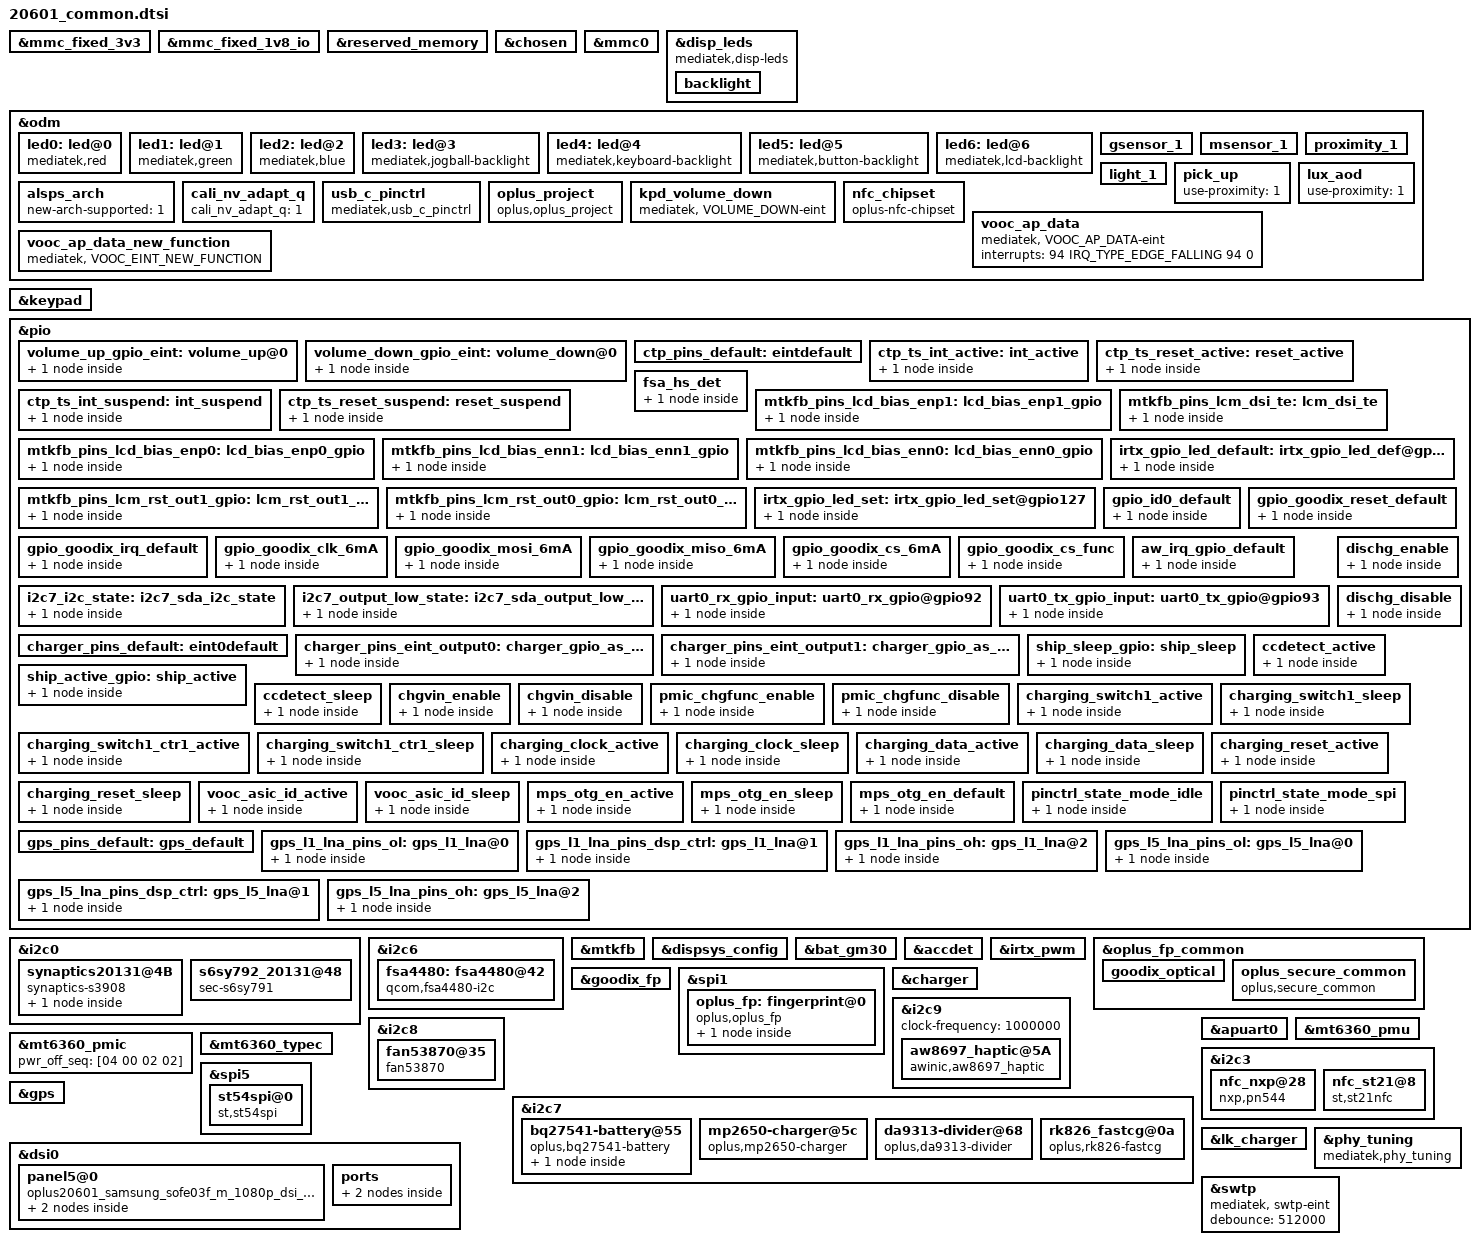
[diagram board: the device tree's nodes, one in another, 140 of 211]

&mmc_fixed_3v3 {
	status = "okay";
	regulator-name = "mmc_power";
	regulator-min-microvolt = <3300000>;
	regulator-max-microvolt = <3300000>;
	enable-active-high;
	regulator-always-on;
};

&mmc_fixed_1v8_io {
	status = "okay";
	regulator-name = "mmc_io";
	regulator-min-microvolt = <1800000>;
	regulator-max-microvolt = <1800000>;
	enable-active-high;
	regulator-always-on;
};

&reserved_memory {
};

/* chosen */
&chosen {

	atag,videolfb-fb_base_l = <0x7e020000>;
	atag,videolfb-fb_base_h = <0x0>;
	atag,videolfb-islcmfound = <1>;
	atag,videolfb-islcm_inited = <0>;
	atag,videolfb-fps= <6000>;
	atag,videolfb-vramSize= <0x1be0000>;
	atag,videolfb-lcmname=
		"nt35595_fhd_dsi_cmd_truly_nt50358_drv";
};

&mmc0 {
	status = "okay";
	/* pinctrl-names = "default", "state_uhs"; */
	/* pinctrl-0 = <&mmc0_pins_default>; */
	/* pinctrl-1 = <&mmc0_pins_uhs>; */
	bus-width = <8>;
	max-frequency = <5000000>;
	cap-mmc-highspeed;
	no-sdio;
	no-sd;
	vmmc-supply = <&mmc_fixed_3v3>;
	vqmmc-supply = <&mmc_fixed_1v8_io>;
	non-removable;
};

&disp_leds {
        compatible = "mediatek,disp-leds";
        backlight {
                label = "lcd-backlight";
                max-brightness = <4095>;
                led-bits = <12>;
                trans-bits = <12>;
                default-state = "on";
        };
};

&odm {
	led0:led@0 {
		compatible = "mediatek,red";
		led_mode = <0>;
		data = <1>;
		pwm_config = <0 0 0 0 0>;
	};
	led1:led@1 {
		compatible = "mediatek,green";
		led_mode = <0>;
		data = <1>;
		pwm_config = <0 0 0 0 0>;
	};
	led2:led@2 {
		compatible = "mediatek,blue";
		led_mode = <0>;
		data = <1>;
		pwm_config = <0 0 0 0 0>;
	};
	led3:led@3 {
		compatible = "mediatek,jogball-backlight";
		led_mode = <0>;
		data = <1>;
		pwm_config = <0 0 0 0 0>;
	};
	led4:led@4 {
		compatible = "mediatek,keyboard-backlight";
		led_mode = <0>;
		data = <1>;
		pwm_config = <0 0 0 0 0>;
	};
	led5:led@5 {
		compatible = "mediatek,button-backlight";
		led_mode = <0>;
		data = <1>;
		pwm_config = <0 0 0 0 0>;
	};
	led6:led@6 {
		compatible = "mediatek,lcd-backlight";
		//led_mode = <5>;
		//#else
		led_mode = <4>;
		//#endif
		data = <1>;
		pwm_config = <0 1 0 0 0>;
	};

/* sensor start */
	/*
	enum {
		LIS3DH,
		LSM6DS3,
		BMI160,
		LIS2HH12,
		LSM6DSM,
		BMI2XY,
		LSM6DSO,
	};
	*/
	gsensor_1: gsensor_1 {
		status = "okay";
		sensor_name = <2>;//BMI160
		device_name = "bmi160";
		i2c_num = <2>;
		i2c_addr = <0>;
		direction = <7>;
		eint_num = <3>;
		step_count_7_en = <1>;
		config_miso = <0>;
		correct_y_bias = <0>;
		cali_nv_adapt_q_flag = <1>;
	};

	/*
	enum {
		AKM09911,
		MMC3530,
		MMC5603,
		MXG4300,
	};
	*/
	msensor_1: msensor_1 {
		status = "okay";
		sensor_name = <0>;//AKM09911
		i2c_num = <0>;
		i2c_addr = <12>;
		direction = <2>;
		eint_num = <0>;
		soft-mag-parameter = <9237 0 1513 0 780 0 1513 0 10462 0 778 1 780 0 778 1 10745 0>;
	};
	/*
	enum {
		TMD2725,
		APSD9922,
		STK3335,
		STK3331,
		STK2232,
		TCS3701,
		STK32600,
		STK33502,
	};
	*/
		proximity_1: proximity_1 {
		status = "okay";
		sensor_name = <7>;//STK33502
		i2c_num = <0>;
		i2c_addr = <0x46>;
		direction = <4>;
		eint_num = <4>;
		low_step = <150>;
		high_step = <200>;
		low_limit = <200>;
		high_limit = <300>;
		dirty_low_step = <100>;
		dirty_high_step = <150>;
		ps_dirty_limit = <1023>;
		ps_ir_limit = <500>;
		ps_adjust_min = <0>;
		ps_adjust_max = <600>;
		sampling_count = <5>;
		step_max = <400>;
		step_min = <100>;
		step_div = <2000>;
		anti_shake_delta = <70>;
		dynamic_cali_max = <3000>;
		raw2offset_radio = <1000>;
		offset_max = <60000>;
		offset_range_min = <0>;
		offset_range_max = <65534>;
		force_cali_limit = <2000>;
		cali_jitter_limit = <30>;
		cal_offset_margin = <3000>;
	};
	light_1: light_1 {
		status = "okay";
		sensor_name = <7>;//STK33502
		i2c_num = <0>;
		i2c_addr = <0x46>;
		direction = <4>;
		eint_num = <4>;
		als_ratio = <110>;
		als_buffer_length =<4>;
		als_type = <1>;//<1-normal;2-under screen;3-normal needed compensation>
		device_name = "stk33502";
		coefficient_mode = <1>;
	};
	pick_up: pick_up {
		status = "okay";
		use-proximity = <1>;
	};
	lux_aod: lux_aod {
		status = "okay";
		use-proximity = <1>;
	};
	alsps_arch: alsps_arch {
		status = "okay";
		new-arch-supported = <1>;
	};
	cali_nv_adapt_q: cali_nv_adapt_q {
		status = "okay";
		cali_nv_adapt_q = <1>;
	};
/* sensor end */
	usb_c_pinctrl:usb_c_pinctrl {
		compatible = "mediatek,usb_c_pinctrl";
	};
/*OPLUS_FEATURE_TP_BASIC oplus project start */
	oplus_project:oplus_project {
		compatible = "oplus,oplus_project";
	};
/*endif*/
//#ifdef OPLUS_FEATURE_TP_BASIC
        kpd_volume_down:kpd_volume_down {
                compatible = "mediatek, VOLUME_DOWN-eint";
                interrupt-parent = <&pio>;
                interrupts = <155 IRQ_TYPE_EDGE_FALLING 155 0>;
                debounce = <32000>;
                status = "okay";
        };

//#endif OPLUS_FEATURE_TP_BASIC

    nfc_chipset:nfc_chipset {
        compatible = "oplus-nfc-chipset";
        chipset-20131 = "SN100T";
        chipset-20601 = "ST54H";
        chipset-20602 = "ST54H";
        chipset-20660 = "ST21H";
    };
//#endif /* OPLUS_FEATURE_NFC_CONSOFT */
};
//#ifdef OPLUS_FEATURE_TP_BASIC
&keypad {
        keypad,volume-up        = <&pio 20 0x00>;
        keypad,volume-down      = <&pio 155 0x00>;
        pinctrl-names = "volume_up_as_int", "volume_down_as_int";
        pinctrl-0 = <&volume_up_gpio_eint>;
        pinctrl-1 = <&volume_down_gpio_eint>;
        status = "okay";
};

&pio {
        volume_up_gpio_eint:volume_up@0{
                pins_cmd_dat {
                        pinmux = <PINMUX_GPIO59__FUNC_GPIO59>;
                        slew-rate = <0>;  /*direction 0:in, 1:out*/
                        input-enable;
                };
        };

        volume_down_gpio_eint:volume_down@0{
                pins_cmd_dat {
                        pinmux = <PINMUX_GPIO155__FUNC_GPIO155>;
                        slew-rate = <0>;  /*direction 0:in, 1:out*/
                        input-enable;
                };
        };
};
//#endif OPLUS_FEATURE_TP_BASIC
//#ifdef OPLUS_FEATURE_TP_BASIC
&i2c0 {

	synaptics20131@4B {
		compatible = "synaptics-s3908";
		reg = <0x4B>;
		chip-name = "S3908";

		/* Interrupt && Irq-gpio */
		interrupt-parent = <&pio>;
		interrupts = <21 0x2008>;

		/* Power Config */
		vdd_2v8-supply  = <&mt_pmic_vtp_ldo_reg>;
		vdd_2v8_volt = <3000000>;
		/* Other HW Resource */

		irq-gpio = <&pio 21 0x2008>;
		reset-gpio = <&pio 20 0x1>;
		pinctrl-names = "default";
		pinctrl-0 = <&ctp_ts_int_active &ctp_ts_reset_suspend>;

		touchpanel,max-num-support = <10>;
		touchpanel,tx-rx-num = <16 36>;
		touchpanel,panel-coords = <1080 2400>;
		touchpanel,display-coords = <1080 2400>;
		touchpanel,touchmajor-limit = <32 54>;
		//touchpanel,elimination-range = <20 200 200>;
		touchpanel,int-mode = <1>; /*0: interrupt and disable, 1:interrupt and not disable*/
		touchpanel,smooth-level = <0 1 2 3 8 10>;
		touchpanel,sensitive-level = <0 88 70 64 45 10>;
		vid_len = <2>;
		tp_type = <8>; /*type:8 BOE*/
		platform_support_project = <20131 20133 20255 20257 20601 20602 20660>;
		platform_support_project_dir = <20131 20131 20131 20131 20601 20601 20601>;
                platform_support_project_commandline = "oplus20131_boe_nt37800_1080p_dsi_cmd","oplus20131_boe_nt37800_1080p_dsi_cmd","oplus20131_boe_nt37800_1080p_dsi_cmd","oplus20131_boe_nt37800_1080p_dsi_cmd","default_commandline","default_commandline","default_commandline";
		/* SW Support Feature Control */
		black_gesture_support;
		fw_edge_limit_support;
		charger_pump_support;
		//spurious_fingerprint_support;
		fw_update_app_support;
		smart_gesture_support;
		game_switch_support;
		//kernel_grip_support;
		//health_monitor_support;
		fingerprint_underscreen_support;
		freq_hop_simulate_support;
		report_flow_unlock_support;
		screenoff_fingerprint_info_support;
		headset_pump_support;
		pressure_report_support;
		irq_need_dev_resume_ok;

		/*
		 *Virtual Key Config:
		 *1:touchpanel,button-type: <virtualkey_type  supportted_button-map>
		 *virtualkey_type:
		 *Type 1: using board_properties
		 *Type 2: using same IC (button zone&& touch zone are seprate)
		 *Type 3: using diffrent IC (button zone&& touch zone are seprate)
		 *Type 4: No need of virtual key process
		 *supportted_button-map:select|menu|home|back
		 *
		 *2:touchpanel,button-map
		 *type (X1,Y1)(X2,Y2)(X3,Y3)(Width_X,Hight_Y)--Only when button-type is 0
		 */
		touchpanel,button-type = <4>;
		touchpanel.button-TRx = <0 0>;
		S3908 {
			report_rate_default = <60>;
			report_rate_game_value = <2>;
		};
	};

	s6sy792_20131@48 {
		compatible = "sec-s6sy791";
		reg = <0x48>;
		chip-name = "S6SY792";

                /* Interrupt && Irq-gpio */
                interrupt-parent = <&pio>;
                interrupts = <21 0x2008>;

                /* Power Config */
                vdd_2v8-supply  = <&mt_pmic_vtp_ldo_reg>;
                vdd_2v8_volt = <3000000>;
                /* Other HW Resource */

                irq-gpio = <&pio 21 0x2008>;
                reset-gpio = <&pio 20 0x1>;
                pinctrl-names = "default";
                pinctrl-0 = <&ctp_ts_int_active &ctp_ts_reset_suspend>;


		touchpanel,max-num-support = <10>;
                touchpanel,tx-rx-num = <16 36>;
                touchpanel,panel-coords = <1080 2400>;
                touchpanel,display-coords = <1080 2400>;
                touchpanel,touchmajor-limit = <32 54>;
                //touchpanel,elimination-range = <20 200 200>;

                vid_len = <2>;
                tp_type = <8>; /*type:8 SAMSUNG*/
                platform_support_project = <20131 20133 20255 20257>;
        	platform_support_project_dir = <20131 20131 20131 20131>;
                platform_support_project_commandline = "oplus20131_samsung_ana6705_1080p_dsi_cmd","oplus20131_samsung_ana6705_1080p_dsi_cmd","oplus20131_samsung_ana6705_1080p_dsi_cmd","oplus20131_samsung_ana6705_1080p_dsi_cmd";

                /* SW Support Feature Control */
                black_gesture_support;
                //fw_edge_limit_support;
                charger_pump_support;
                //spurious_fingerprint_support;
                fw_update_app_support;
                smart_gesture_support;
                game_switch_support;
                //kernel_grip_support;
                //health_monitor_support;
                fingerprint_underscreen_support;
                headset_pump_support;
                pressure_report_support;

		/*
                 *Virtual Key Config:
                 *1:touchpanel,button-type: <virtualkey_type  supportted_button-map>
                 *virtualkey_type:
                 *Type 1: using board_properties
                 *Type 2: using same IC (button zone&& touch zone are seprate)
                 *Type 3: using diffrent IC (button zone&& touch zone are seprate)
                 *Type 4: No need of virtual key process
                 *supportted_button-map:select|menu|home|back
                 *
                 *2:touchpanel,button-map
                 *type (X1,Y1)(X2,Y2)(X3,Y3)(Width_X,Hight_Y)--Only when button-type is 0
                 */
                touchpanel,button-type = <4>;
                touchpanel.button-TRx = <0 0>;
	};
};

&pio {
	ctp_pins_default: eintdefault {
	};
	ctp_ts_int_active: int_active {
		pins_cmd_dat {
			pinmux = <PINMUX_GPIO21__FUNC_GPIO21>;
			slew-rate = <0>;
			bias-pull-up;
		};
	};
	ctp_ts_reset_active: reset_active {
		pins_cmd_dat {
			pinmux = <PINMUX_GPIO20__FUNC_GPIO20>;
			slew-rate = <1>;
			output-high;
		};
	};
	ctp_ts_int_suspend: int_suspend {
		pins_cmd_dat {
			pinmux = <PINMUX_GPIO21__FUNC_GPIO21>;
			slew-rate = <1>;
			output-low;
		};
	};
	ctp_ts_reset_suspend: reset_suspend {
		pins_cmd_dat {
			pinmux = <PINMUX_GPIO20__FUNC_GPIO20>;
			slew-rate = <1>;
			output-low;
		};
	};
};
//#endif OPLUS_FEATURE_TP_BASIC

//#ifdef OPLUS_ARCH_EXTENDS
&i2c6 {
	fsa4480: fsa4480@42 {
		compatible = "qcom,fsa4480-i2c";
		reg = <0x42>;
		pinctrl-names = "default";
		pinctrl-0 = <&fsa_hs_det>;
		fsa4480,hs-det-gpio = <&pio 54 0>;
	};
};

&pio {
	fsa_hs_det: fsa_hs_det {
		pins_cmd_dat {
			pinmux = <PINMUX_GPIO54__FUNC_GPIO54>;
			slew-rate = <1>;  /*direction 0:in, 1:out*/
			output-high;
		};
	};
	/*
	aud_gpio_i2s0_on: aud_gpio_i2s0_on {
		pins_cmd1_dat {
			pinmux = <PINMUX_GPIO34__FUNC_I2S3_DI>;
		};
	};*/
};
//#endif /*OPLUS_ARCH_EXTENDS*/

/* DISPSYS GPIO standardization */
&pio {
	mtkfb_pins_lcd_bias_enp1: lcd_bias_enp1_gpio {
		pins_cmd_dat {
			pinmux = <PINMUX_GPIO28__FUNC_GPIO28>;
			slew-rate = <1>;
			output-high;
		};
	};

	mtkfb_pins_lcd_bias_enp0: lcd_bias_enp0_gpio {
		pins_cmd_dat {
			pinmux = <PINMUX_GPIO28__FUNC_GPIO28>;
			slew-rate = <1>;
			output-low;
		};
	};

	mtkfb_pins_lcd_bias_enn1: lcd_bias_enn1_gpio {
		pins_cmd_dat {
			pinmux = <PINMUX_GPIO29__FUNC_GPIO29>;
			slew-rate = <1>;
			output-high;
		};
	};

	mtkfb_pins_lcd_bias_enn0: lcd_bias_enn0_gpio {
		pins_cmd_dat {
			pinmux = <PINMUX_GPIO29__FUNC_GPIO29>;
			slew-rate = <1>;
			output-low;
		};
	};

	mtkfb_pins_lcm_rst_out1_gpio: lcm_rst_out1_gpio {
		pins_cmd_dat {
			pinmux = <PINMUX_GPIO42__FUNC_GPIO42>;
			slew-rate = <1>;
			output-high;
		};
	};

	mtkfb_pins_lcm_rst_out0_gpio: lcm_rst_out0_gpio {
		pins_cmd_dat {
			pinmux = <PINMUX_GPIO42__FUNC_GPIO42>;
			slew-rate = <1>;
			output-low;
		};
	};

	mtkfb_pins_lcm_dsi_te: lcm_dsi_te {
		pins_cmd_dat {
			pinmux = <PINMUX_GPIO41__FUNC_DSI_TE>;
		};
	};
};

&mtkfb {
	pinctrl-names = "lcd_bias_enp1_gpio", "lcd_bias_enp0_gpio",
		"lcd_bias_enn1_gpio", "lcd_bias_enn0_gpio",
		"lcm_rst_out1_gpio", "lcm_rst_out0_gpio",
		"mode_te_te";
	pinctrl-0 = <&mtkfb_pins_lcd_bias_enp1>;
	pinctrl-1 = <&mtkfb_pins_lcd_bias_enp0>;
	pinctrl-2 = <&mtkfb_pins_lcd_bias_enn1>;
	pinctrl-3 = <&mtkfb_pins_lcd_bias_enn0>;
	pinctrl-4 = <&mtkfb_pins_lcm_rst_out1_gpio>;
	pinctrl-5 = <&mtkfb_pins_lcm_rst_out0_gpio>;
	pinctrl-6 = <&mtkfb_pins_lcm_dsi_te>;
	status = "okay";
};

&dispsys_config {
	pinctrl-names =
		"lcm_rst_out1_gpio", "lcm_rst_out0_gpio",
		"mode_te_te";
	pinctrl-0 = <&mtkfb_pins_lcm_rst_out1_gpio>;
	pinctrl-1 = <&mtkfb_pins_lcm_rst_out0_gpio>;
	pinctrl-2 = <&mtkfb_pins_lcm_dsi_te>;
	status = "okay";

        helper-value = <0>, /*MTK_DRM_OPT_STAGE*/
                <1>, /*MTK_DRM_OPT_USE_CMDQ*/
                <1>, /*MTK_DRM_OPT_USE_M4U*/
                <0>, /*MTK_DRM_OPT_SODI_SUPPORT*/
                <1>, /*MTK_DRM_OPT_IDLE_MGR*/
                <0>, /*MTK_DRM_OPT_IDLEMGR_SWTCH_DECOUPLE*/
                <1>, /*MTK_DRM_OPT_IDLEMGR_BY_REPAINT*/
                <0>, /*MTK_DRM_OPT_IDLEMGR_ENTER_ULPS*/
                <0>, /*MTK_DRM_OPT_IDLEMGR_KEEP_LP11*/
                <0>, /*MTK_DRM_OPT_DYNAMIC_RDMA_GOLDEN_SETTING*/
                <1>, /*MTK_DRM_OPT_IDLEMGR_DISABLE_ROUTINE_IRQ*/
                <0>, /*MTK_DRM_OPT_MET_LOG*/
                <1>, /*MTK_DRM_OPT_USE_PQ*/
                <1>, /*MTK_DRM_OPT_ESD_CHECK_RECOVERY*/
                <1>, /*MTK_DRM_OPT_ESD_CHECK_SWITCH*/
                <1>, /*MTK_DRM_OPT_PRESENT_FENCE*/
                <0>, /*MTK_DRM_OPT_RDMA_UNDERFLOW_AEE*/
                <0>, /*MTK_DRM_OPT_DSI_UNDERRUN_AEE*/
                <1>, /*MTK_DRM_OPT_HRT*/
                <1>, /*MTK_DRM_OPT_HRT_MODE*/
                <0>, /*MTK_DRM_OPT_DELAYED_TRIGGER*/
                <1>, /*MTK_DRM_OPT_OVL_EXT_LAYER*/
                <0>, /*MTK_DRM_OPT_AOD*/
                <1>, /*MTK_DRM_OPT_RPO*/
                <0>, /*MTK_DRM_OPT_DUAL_PIPE*/
                <0>, /*MTK_DRM_OPT_DC_BY_HRT*/
                <1>, /*MTK_DRM_OPT_OVL_WCG*/
                <0>, /*MTK_DRM_OPT_OVL_SBCH*/
                <1>, /*MTK_DRM_OPT_COMMIT_NO_WAIT_VBLANK*/
                <0>, /*MTK_DRM_OPT_MET*/
                <0>, /*MTK_DRM_OPT_REG_PARSER_RAW_DUMP*/
                <0>, /*MTK_DRM_OPT_VP_PQ*/
                <0>, /*MTK_DRM_OPT_GAME_PQ*/
                <0>, /*MTK_DRM_OPT_MMPATH*/
                <1>, /*MTK_DRM_OPT_HBM*/
                <0>, /*MTK_DRM_OPT_VDS_PATH_SWITCH*/
                <0>, /*MTK_DRM_OPT_LAYER_REC*/
                <1>, /*MTK_DRM_OPT_CLEAR_LAYER*/
                <1>, /*MTK_DRM_OPT_SF_PF*/
                <1>, /*MTK_DRM_OPT_PRIM_DUAL_PIPE*/
                <1>; /*MTK_DRM_OPT_DYN_MIPI_CHANGE*/
};

&bat_gm30 {
	DISABLE_MTKBATTERY = <(1)>;
	enable_tmp_intr_suspend = <(1)>;
};

/* DISPSYS GPIO standardization end */

/* accdet start */
&accdet {
	/* accdet micbias voltage: 0x09:2.85v 0x08:2.8v 0x07,
	 * 2.7v;0x05,2.5v;0x02,1.9v
	 */
	accdet-mic-vol = <8>;
	/* accdet pwm_width, pwm_thresh, fall_delay, rise_delay
	 * debounce0, debounce1, debounce3, debounce4
	 * eint pwm_width, eint pwm_thresh
	 * eint deb(debounce0, debounce1, debounce2, debounce3), inv_debounce
	 */
	headset-mode-setting = <0x500 0x500 1 0x1f0
				0x800 0x800 0x20 0x44
				0x4 0x1
				0x5 0x3 0x3 0x5 0xe>;
	accdet-plugout-debounce = <1>;
	/*1:ACC mode, 2:low cost without in bias, 6:low cost with in bias*/
	accdet-mic-mode = <2>;
	/*0--MD_MAX--UP_MAX--DW_MAX*/
	headset-three-key-threshold = <0 82 170 306>;
	headset-three-key-threshold-CDD = <0 121 192 600>;
	/*0--MD_MAX--VOICE_MAX--UP_MAX--DW_MAX*/
	headset-four-key-threshold = <0 58 121 192 400>;

	/* select VTH to 2v and 500k, use internal resitance */
	eint_use_ext_res = <0>;
	status = "okay";

	/* add that is to rm the unplug headset pop */
	remove_unplug_pop = <1>;
};
/* accdet end */

/* IRTX GPIO Start */
&irtx_pwm {
	pinctrl-names = "irtx_gpio_led_default", "irtx_gpio_led_set";
	pinctrl-0 = <&irtx_gpio_led_default>;
	pinctrl-1 = <&irtx_gpio_led_set>;
	status = "okay";
};
&pio {
	/* IRTX GPIO Settings -Start */
	/* default: GPIO0, output, high */
	irtx_gpio_led_default:irtx_gpio_led_def@gpio127 {
		pins_cmd_dat {
			pinmux = <PINMUX_GPIO127__FUNC_GPIO127>;
			slew-rate = <1>;
			bias-disable;
			output-low;
			input-schmitt-enable = <0>;
		};
	};

	irtx_gpio_led_set:irtx_gpio_led_set@gpio127 {
		pins_cmd_dat {
			pinmux = <PINMUX_GPIO127__FUNC_PWM_3>;
			slew-rate = <1>;
			output-high;
		};
	};
}; /* IRTX GPIO Settings -End */

/* FINGERPRINT start */
//ifdef OPLUS_FEATURE_FINGERPRINT
&oplus_fp_common {
    oplus,fp_gpio_num = <1>;
    oplus,fp_gpio_0 = <&pio 190 0x0>;
    pinctrl-names = "default";
    pinctrl-0 = <&gpio_id0_default>;
    goodix_optical {
        oplus,fp-id = <0>; // fp id mapping table
        vendor-chip = <11>; // please refer to the struct fp_vendor_t in oplus_fp_commmon.n
        eng-menu = "-1,-1"; // represents SNR, inclination test item in engineer menu, and 0/1 means off/on
        chip-name = "G_OPTICAL_G6_7.0";  // /proc/fp_id, will be displayed in engineer menu
	};


//#ifdef OPLUS_FEATURE_SECURITY_COMMON
	oplus_secure_common:oplus_secure_common {
		compatible = "oplus,secure_common";
		oplus,sec_reg_num = <0>;
		oplus,sec_en_anti_reg = <0>;
		oplus,sec_override1_reg = <0>;
		oplus,override1_en_value = <0>;
	};
//#endif  OPLUS_FEATURE_SECURITY_COMMON

};

&pio{
	gpio_id0_default: gpio_id0_default {
		pins_cmd_dat {
			pinmux = <PINMUX_GPIO190__FUNC_GPIO190>;
			slew-rate = <0>;
			bias-pull-up = <00>;
			input-enable;
		};
	};
};

&goodix_fp {
	goodix,gpio_irq = <&pio 15 0x00>;
	goodix,gpio_reset = <&pio 14 0x00>;
	goodix,gpio_cs = <&pio 157 0x00>;
	pinctrl-names = "default", "gf_spi_drive_6mA", "gf_cs_func";
	pinctrl-0 = <&gpio_goodix_irq_default>, <&gpio_goodix_reset_default>;
	pinctrl-1 = <&gpio_goodix_clk_6mA>, <&gpio_goodix_mosi_6mA>, <&gpio_goodix_miso_6mA>, <&gpio_goodix_cs_6mA>;
	pinctrl-2 = <&gpio_goodix_cs_func>;
	status = "okay";
};

&spi1 {
#address-cells = <1>;
#size-cells = <0>;
status = "okay";
oplus_fp: fingerprint@0 {
		 compatible = "oplus,oplus_fp";
		 reg = <0>;
		 spi-max-frequency = <8000000>;
		 spi-id = <1>;
		 spi-irq = <39>;
		 spi-reg = <11010000>;
		 avdd-supply = <&mt_pmic_vmch_ldo_reg>;
		 avdd-config = <3300000 3300000 150000>;
		 power-num = <1>;
		 status = "okay";
		 notify_tpinfo_flag = <1>;
		 power_source_1 {
			 power-mode = <1>;
			 power-name = "avdd";
			 power-config = "avdd-config";
			 delay-time = <0>;
		 };
	 };
};
// 1 = ldo power, refer to oplus_fp_common.h
&pio{
gpio_goodix_reset_default: gpio_goodix_reset_default {
				   pins_cmd_dat {
					   pinmux = <PINMUX_GPIO14__FUNC_GPIO14>;
					   slew-rate = <1>;
					   output-low;
				   };
			   };
gpio_goodix_irq_default: gpio_goodix_irq_default {
				 pins_cmd_dat {
					 pinmux = <PINMUX_GPIO15__FUNC_GPIO15>;
					 slew-rate = <0>;
					 bias-pull-down;
				 };
			 };
gpio_goodix_clk_6mA: gpio_goodix_clk_6mA {
			     pins_cmd_dat {
				      pinmux = <PINMUX_GPIO156__FUNC_SPI1_A_CLK>;
				      drive-strength = <2>;
			     };
		     };
gpio_goodix_mosi_6mA: gpio_goodix_mosi_6mA {
			      pins_cmd_dat {
				      pinmux = <PINMUX_GPIO159__FUNC_SPI1_A_MO>;
				      drive-strength = <2>;
			      };
		      };
gpio_goodix_miso_6mA: gpio_goodix_miso_6mA {
			      pins_cmd_dat {
				      pinmux = <PINMUX_GPIO158__FUNC_SPI1_A_MI>;
				      drive-strength = <3>;
			      };
		      };
gpio_goodix_cs_6mA: gpio_goodix_cs_6mA {
			    pins_cmd_dat {
				    pinmux = <PINMUX_GPIO157__FUNC_SPI1_A_CSB>;
				    drive-strength = <2>;
			    };
		    };
gpio_goodix_cs_func: gpio_goodix_cs_func {
			     pins_cmd_dat {
				     pinmux = <PINMUX_GPIO157__FUNC_SPI1_A_CSB>;
				     drive-strength = <2>;
			     };
		     };
};
//#endif
/* FINGERPRINT end */
//#ifdef OPLUS_FEATURE_CHG_BASIC
&charger {
	io-channels = <&auxadc 3>,
		<&auxadc 4>,
		<&auxadc 5>;
	io-channel-names = "auxadc3-chargeric_temp",
		"auxadc4-usb_temp_v_l",
		"auxadc5-usb_temp_v_r";

	pinctrl-names = "default", "charger_gpio_as_output_low", "charger_gpio_as_output_high", "ship_sleep", "ship_active",
		"dischg_enable", "dischg_disable", "chgvin_enable", "chgvin_disable","pmic_chgfunc_enable", "pmic_chgfunc_disable",
		"ccdetect_active","ccdetect_sleep";
	pinctrl-0 = <&charger_pins_default>;
	pinctrl-1 = <&charger_pins_eint_output0>;	//USB_ON -> USB_SWITCH:(UART && USB)
	pinctrl-2 = <&charger_pins_eint_output1>;
	pinctrl-3 = <&ship_sleep_gpio>;				//ship_mode
	pinctrl-4 = <&ship_active_gpio>;
	pinctrl-5 = <&dischg_enable>;				//usb_hightemp_port
	pinctrl-6 = <&dischg_disable>;
	pinctrl-7 = <&chgvin_enable>;					//EVB GPIO30 chgvin
	pinctrl-8 = <&chgvin_disable>;
	pinctrl-9 = <&pmic_chgfunc_enable>;				//EVB GPIO26 chg_enable
	pinctrl-10 = <&pmic_chgfunc_disable>;
	//pinctrl-5 = <&shortc_active_gpio>;
	pinctrl-11 = <&ccdetect_active>;
	pinctrl-12 = <&ccdetect_sleep>;
	qcom,hv_flashled_support;
	qcom,chargerid_support;
	qcom,input_current_charger_ma = <2000>;
	qcom,pd_input_current_charger_ma = <2000>;
	qcom,qc_input_current_charger_ma = <2000>;
	qcom,input_current_usb_ma = <500>;

	qcom,input_current_led_ma = <1200>;
	qcom,input_current_led_ma_high = <1200>;
	qcom,input_current_led_ma_warm = <1500>;
	qcom,input_current_led_ma_normal = <2000>;
	qcom,led_warm_bat_decidegc = <350>;
	qcom,led_high_bat_decidegc = <370>;

	qcom,input_current_camera_ma = <1200>;
	qcom,input_current_cdp_ma = <1500>;

	qcom,input_current_vooc_led_ma_high = <1200>;
	qcom,input_current_vooc_led_ma_warm = <1800>;
	qcom,input_current_vooc_led_ma_normal = <3600>;
	qcom,input_current_vooc_ma_normal = <3600>;
	qcom,vooc_temp_bat_normal_decidegc = <350>;
	qcom,input_current_vooc_ma_warm = <3200>;
	qcom,vooc_temp_bat_warm_decidegc = <370>;
	qcom,input_current_vooc_ma_high = <2200>;
	qcom,vooc_temp_bat_hot_decidegc = <440>;

	qcom,charger_current_vooc_ma_normal = <1800>;

	qcom,chg_ctrl_by_calling;
	qcom,input_current_calling_ma = <1500>;

	qcom,overtemp_bat_decidegc = <350>;
	qcom,iterm_disabled = <0>;
	sw_full_count = <25>;
	qcom,iterm_ma = <115>;
	qcom,recharge-mv = <100>;
	qcom,batt_capacity_mah = <4500>;/*typical capacity*/

	qcom,removed_bat_decidegc = <190>;  /*<-19C*/

	qcom,cold_bat_decidegc = <20>;  /*-2C~0C*/
	qcom,temp_cold_vfloat_mv = <3980>;
	qcom,temp_cold_fastchg_current_ma = <300>;

	qcom,little_cold_bat_decidegc = <0>;    /*0C~5C*/
	qcom,temp_little_cold_vfloat_mv = <4435>;
	qcom,temp_little_cold_fastchg_current_ma_high = <950>;
	qcom,temp_little_cold_fastchg_current_ma_low = <950>;
	qcom,temp_little_cold_fastchg_current_ma = <950>;
	qcom,pd_temp_little_cold_fastchg_current_ma_high = <1800>;
	qcom,pd_temp_little_cold_fastchg_current_ma_low = <1500>;
	qcom,qc_temp_little_cold_fastchg_current_ma_high = <1800>;
	qcom,qc_temp_little_cold_fastchg_current_ma_low = <1500>;

	qcom,cool_bat_decidegc = <50>;  /*5C~12C*/
	qcom,temp_cool_vfloat_mv = <4435>;
	qcom,temp_cool_fastchg_current_ma_high = <1100>;
	qcom,temp_cool_fastchg_current_ma_low = <1100>;
	qcom,pd_temp_cool_fastchg_current_ma_high = <2000>;
	qcom,pd_temp_cool_fastchg_current_ma_low = <1500>;
	qcom,qc_temp_cool_fastchg_current_ma_high = <2000>;
	qcom,qc_temp_cool_fastchg_current_ma_low = <1500>;

	qcom,little_cool_bat_decidegc = <120>;  /*12C~16C*/
	qcom,temp_little_cool_vfloat_mv = <4435>;
	qcom,temp_little_cool_fastchg_current_ma = <1100>;
	qcom,pd_temp_little_cool_fastchg_current_ma = <2000>;
	qcom,qc_temp_little_cool_fastchg_current_ma = <2000>;

	qcom,normal_bat_decidegc = <160>;       /*16C~44C*/
	qcom,temp_normal_fastchg_current_ma = <1100>;
	qcom,temp_normal_vfloat_mv = <4435>;
	qcom,pd_temp_normal_fastchg_current_ma = <2000>;
	qcom,qc_temp_normal_fastchg_current_ma = <2000>;

	qcom,warm_bat_decidegc = <450>;         /*45C~53C*/ /*8pin Bat Vooc project need add 3 degree C*/
	qcom,temp_warm_vfloat_mv = <4130>;
	qcom,temp_warm_fastchg_current_ma = <550>;
	qcom,pd_temp_warm_fastchg_current_ma = <600>;
	qcom,qc_temp_warm_fastchg_current_ma = <600>;
	qcom,temp_warm_fastchg_current_ma_led_on = <250>;

	qcom,hot_bat_decidegc = <530>;

	qcom,non_standard_vfloat_mv = <3980>;
	qcom,non_standard_fastchg_current_ma = <512>;

	qcom,short_c_bat_cv_mv = <4330>;
	qcom,short_c_bat_vfloat_mv = <3800>;
	qcom,short_c_bat_fastchg_current_ma = <512>;

	qcom,cold_vfloat_sw_limit = <3930>;
	qcom,little_cold_vfloat_sw_limit = <4385>;
	qcom,cool_vfloat_sw_limit = <4385>;
	qcom,little_cool_vfloat_sw_limit = <4385>;
	qcom,normal_vfloat_sw_limit = <4385>;
	qcom,warm_vfloat_sw_limit = <4080>;
	qcom,non_standard_vfloat_sw_limit = <3930>;
	qcom,short_c_bat_vfloat_sw_limit = <3750>;

	qcom,max_chg_time_sec = <64800>;
	qcom,charger_hv_thr = <9900>;
	qcom,charger_recv_thr = <9500>;
	qcom,charger_lv_thr = <3400>;
	qcom,vbatt_full_thr = <4435>;
	qcom,vbatt_hv_thr = <4600>;
	qcom,vfloat_step_mv = <8>;
	qcom,non_standard_vfloat_over_sw_limit = <3990>;
	qcom,cold_vfloat_over_sw_limit = <3990>;
	qcom,little_cold_vfloat_over_sw_limit = <4445>;
	qcom,cool_vfloat_over_sw_limit = <4445>;
	qcom,little_cool_vfloat_over_sw_limit = <4445>;
	qcom,normal_vfloat_over_sw_limit = <4445>;
	qcom,warm_vfloat_over_sw_limit = <4140>;

	qcom,vbatt_power_off = <3300>;
	qcom,vbatt_soc_1 = <3310>;
	qcom,vooc_project = <3>;
	qcom,vbatt_num = <2>;
	qcom,new_ui_warning_support;
	qcom,ffc_support;
	qcom,dual_ffc;
	recharge_after_full;

	qcom,normal_vterm_hw_inc = <18>;
	qcom,non_normal_vterm_hw_inc = <18>;

	qcom,ff1_normal_fastchg_ma = <550>;
	qcom,ff1_warm_fastchg_ma = <550>;

	qcom,ffc2_normal_fastchg_ma = <350>;/*12C~35c*/
	qcom,ffc2_temp_warm_decidegc = <350>;
	qcom,ffc2_warm_fastchg_ma = <350>;/*35C~40c*/
	qcom,ffc2_temp_high_decidegc = <400>;
	qcom,ffc2_temp_low_decidegc = <120>;

	qcom,ff1_exit_step_ma = <150>;
	qcom,ff1_warm_exit_step_ma = <150>;
	qcom,ffc2_exit_step_ma = <150>;
	qcom,ffc2_warm_exit_step_ma = <150>;

	qcom,ffc_normal_vfloat_sw_limit = <4455>;
	qcom,ffc_temp_normal_vfloat_mv = <4500>;
	qcom,ffc_normal_vfloat_over_sw_limit = <4500>;
	qcom,ffc_warm_vfloat_sw_limit = <4450>;
	qcom,ffc_temp_warm_vfloat_mv = <4500>;
	qcom,ffc_warm_vfloat_over_sw_limit = <4500>;
	qcom,ffc1_temp_normal_vfloat_mv = <4500>;

	qcom,ffc2_normal_vfloat_sw_limit = <4442>;
	qcom,ffc2_temp_normal_vfloat_mv = <4500>;

	qcom,ffc1_normal_vfloat_over_sw_limit = <4500>;
	qcom,ffc2_normal_vfloat_over_sw_limit = <4500>;
	qcom,ffc2_warm_vfloat_sw_limit = <4437>;
	qcom,ffc2_temp_warm_vfloat_mv = <4500>;
	qcom,ffc2_warm_vfloat_over_sw_limit = <4500>;

	qcom,default_iterm_ma = <115>;
	qcom,default_temp_normal_fastchg_current_ma = <1100>;
	qcom,default_normal_vfloat_sw_limit = <4385>;
	qcom,default_temp_normal_vfloat_mv = <4435>;
	qcom,default_normal_vfloat_over_sw_limit = <4445>;

	qcom,default_temp_little_cool_fastchg_current_ma = <1100>;
	qcom,default_little_cool_vfloat_sw_limit = <4385>;
	qcom,default_temp_little_cool_vfloat_mv = <4435>;
	qcom,default_little_cool_vfloat_over_sw_limit = <4445>;

	qcom,vooc_show_ui_soc_decimal;
	qcom,ui_soc_decimal_speedmin = <20>;//2A
	qcom,check_batt_full_by_sw;
	qcom,external_gauge;
	qcom,chg_ctrl_by_lcd;
	qcom,chg_ctrl_by_vooc;
	qcom,chg_ctrl_by_camera;
	qcom,support_ntc_01c_precision;
	qcom,sw_vfloat_over_protect_enable;
	qcom,lpd-disable;
	//for PD9V or QC9V
	qcom,vbatt_pdqc_to_5v_thr = <4100>;
	qcom,vbatt_pdqc_to_9v_thr = <4000>;

	//GPIO config:
	qcom,chargerid_switch-gpio = <&pio 192 0x00>;//USB_ON
	qcom,ship-gpio = <&pio 126 0x00>;		//check
	qcom,dischg-gpio = <&pio 51 0x00>;//VBUS_SHORT
	//qcom,shortc-gpio = <&pio 121 0x00>;
	qcom,ccdetect-gpio = <&pio 5 0x00>;//USB_ACC_INT

	//Lukaili Add for camera flash led
	qcom,chgvin = <&pio 9 0x00>;		//check
	qcom,pmic_chgfunc = <&pio 26 0x00>;		//check
};
//#endif OPLUS_FEATURE_CHG_BASIC
&i2c9 {
    status = "okay";
	clock-frequency = <1000000>;
	
	/* AWINIC AW8697 Haptic */
	aw8697_haptic@5A {
		status = "okay";
		compatible = "awinic,aw8697_haptic";
		reg = <0x5A>;
		reset-gpio = <&pio 185 0x1>;
		irq-gpio = <&pio 135 0x2008>;
		qcom,device_id = <832>;//19065

		pinctrl-names = "default";
		pinctrl-0 = <&aw_irq_gpio_default>;
	};
};

&i2c8 {
	   fan53870@35 {
               compatible = "fan53870";
               reg = <0x35>;
               ldo1_min_vol = <800000>;  /*uV*/
               ldo1_max_vol = <1504000>;
               ldo1_step_vol = <8000>;
       };
};

&pio{
	aw_irq_gpio_default: aw_irq_gpio_default {		//check
		pins_cmd_dat {
			pinmux = <PINMUX_GPIO135__FUNC_GPIO135>;
			slew-rate = <0>;
			bias-pull-up = <11>;
			input-enable;
		};
	};

};
//#ifdef OPLUS_FEATURE_CHG_BASIC
&odm {
	vooc_ap_data:vooc_ap_data {
		compatible = "mediatek, VOOC_AP_DATA-eint";
		interrupts = <94 IRQ_TYPE_EDGE_FALLING 94 0>;
	};
	vooc_ap_data_new_function:vooc_ap_data_new_function {
		compatible = "mediatek, VOOC_EINT_NEW_FUNCTION";
	};
};
//#endif OPLUS_FEATURE_CHG_BASIC
//#ifdef OPLUS_FEATURE_CHG_BASIC
&i2c7 {
       pinctrl-names = "i2c-state", "output-low-state";

       pinctrl-0 = <&i2c7_i2c_state>;
       pinctrl-1 = <&i2c7_output_low_state>;
};
&pio {
       i2c7_i2c_state: i2c7_sda_i2c_state {
                pins_cmd_dat {
                          pinmux = <PINMUX_GPIO112__FUNC_GPIO112>;
                          slew-rate = <0>;
                          bias-pull-up = <11>;
                };
       };
       i2c7_output_low_state: i2c7_sda_output_low_state {
                pins_cmd_dat {
                          pinmux = <PINMUX_GPIO112__FUNC_GPIO112>;
                          slew-rate = <1>;
                          output-low;
                };
       };
};
&i2c7 {
	status = "okay";
	clock-frequency = <100000>;

	bq27541-battery@55 {
		status = "okay";
		compatible = "oplus,bq27541-battery";
		reg = <0x55 0>;
		qcom,modify-soc-smooth;
		qcom,modify-soc-calibration;
		qcom,batt_bq28z610 = <1>;
		qcom,sha1_key_index = <1>;
        //qcom,bq28z610_need_balancing;
		zy,afi_data{
			battery,name = "BLP799";
			qmax_min = <1776>;
			qmax_max = <2553>;
			static_df_checksum_3e = [5C 42];			//len 2
			static_df_checksum_60 = [A5 06];			//len 2
			afi_buf_num = <7>;
			afi_buf_0 = [
				11 D0 11 17 11 D0 11 17 11 D0 11 17 11 D0 11 17
				01 0A 8C 0A 0C 1C 21 34 02 FF CE 02 EC 78 02 FF
				CE 05 C2 0A C2 0A 72 A3 0A 0C D1 02 0C 9F 0D 03
				02 0C D1 0A 79 02 0A AB 09 E3 02 0A 15 07 D0 07
				08 07 08 00 02 09 C4 07 D0 D2 F0 00 02 03 E8 05
				11 EE 05 0E 74 00 0A 01 F4 0A 07 08 0E 74 00 0A
				01 F4 0A 00 0A 05 FF F6 05 0A 0A AB 0B 23 0B 73
				0B A5 0B D7 0C D1 00 0A 00 58 00 2C 11 5D 00 84
				01 60 01 08 11 5D 07 BC 0F A4 0B B0 11 5D 09 CC
				11 88 0D C0 11 5D 03 F4 07 BC 05 D8 09 C4 0D 48
				0E D8 0F A0 00 01 01 2C 01 2C 01 2C 01 2C 00 4B
				03 84 28 01 65 01 6B 03 00 00 46 50 50 00 30 00
				96 00 AF 08 AC 06 B6 1E 3C 5A
				];
			afi_buf_1 = [
				64 63 64 61 00 01 01 02 05 21 1C 00 A2 40 05 57
				00 00 00 03 00 00 0A F0 0A 28 14 0A 14 10 E0 64
				07 D0 00 03 0F 00 14 04 19 C8 00
				];
			afi_buf_2 = [
				AA 01 E9 03 CF 05 2D 07 24 09 A4 0B E7 0D A0 0F
				7E 11 DC 13 BB 15 86 17 0A 19 8F 3B 7E 7D 61 B5
				20 4D 22 6F 24 AE 26 AB 28 06 2A 47 2C E3 2E 81
				30 DF 32 43 34 64 36 C5 38 0E 1A 5F BC 5B 08 CA
				08 C9 33
				];
			afi_buf_3 = [
				11 38 11 38 00 FA FE 47 FE AB FE D5 FC 18 00 8A
				00 32 00 32
				];
			afi_buf_4 = [5C 42];
			afi_buf_5 = [
				FF 01 E9 03 CF 05 2D 07 24 09 A4 0B E7 0D A0 0F
				7E 11 DC 13 BB 15 86 17 0A 19 8F 3B DE 9D DE E0
				20 4D 22 6F 24 AE 26 AB 28 06 2A 47 2C E3 2E 81
				30 DF 32 43 34 64 36 C5 38 0E 1A 7F BC D8 01 01
				00 00 00 00 00 0A 00 08 00 46 00 3C 00 3C 01 3C
				FF F6 FE 0C 32
				];
			afi_buf_6 = [
				84 0A 20 E8 26 4D 24 A3 2A 68 08 F6 0E 37 0C 59
				12 23 10 5D 16 7F 14 B1 1A FB FB 64 FD 21 FF C7
				C1 B4 C3 71 C5 2A C7 ED C9 CF CB EF CD AF CF 2E
				F1 4E F3 2D F5 E9 F7 EC F9 A3 FB C2 FD C5 FF 48
				81 B4 83 77 85 77 87 E8 89 E7 8B C5 8D C4 EF F6
				31 E8 ED BA EB B6 C9 08 C7 C0 E5 B9 C3 A6 E1 71
				DF DD BD C0 DB 1A B9 41 B7 A1 B5 85 D3 F5 B1 BC
				8F BD 8D 56 AB CA 76 5F 78 E8 5A 77 5C 45 5E D1
				A0 8B A2 91 84 1B A6 E6 88 59 35 91 F3 45 D1 49
				AF E7 CD 59 CB 98 E9 D5 07 3B 05 FD 62 A1 60 1C
				B9 6F 5D CE 5B EB 59 F7 57 B9 55 81 53 BC 51 BE
				4F 63 4D A0 4B 64 49 47 47 AF 45 62 BC 77 41 A0
				1F CE 1D D3 1B 57 19 D4 17 17 15 BD 13 F4 11 60
				0F DC 0D 78 0B F9 09 9E 07 71 05 2E 23 E7 FE 5A
				E0 E1 E2 20 E4 26 E6 FE C8 6C 8A EB AC AC ED EB
				90 10 B3 F3 78 F5 B6 D4 E1 38 46 3A F0 DD EC FF
				8C 21 62 A3 A4 A1 CE 07 8A 05 4B 28 09 81 4E 04
				10 51 12 77 75 02 36 92 5E 5F 5B 5B 7C 5D 5F 5E
				61 67 E3 83 A4 CA 86 A0 28 30 6A BC EC 2D 2E AD
				54 31 2B 73 E9 16 BA 76 58 69 DC FB 93 3D 3E DE
				B0 41 A3 A3 3C 45 46 47 48 49 A7 2A 05 4D E2 6E
				19 51 B7 73 7D 55 B7 57 70 59 BF BA 14 5D 5E 5F
				60 61 62 63 64 65 C3 86 21 69 4B AA A4 6D 6E 6F
				70 71 72 73 74 75 76 77 78 79 7A 7B 7C 7D 7E 7F
				80 7E 02 83 E4 C5 C6 87 C8 89 8A 8B 8C 8D 4F 8D
				90 9E FC 99 D4 74 B6 85 98 80 9A 82 1C 9D 5D FF
				A0 2D A2 FC 04 29 A6 BE C8 89 61 AB F3 2F 8E BD
				15 3D 12 B3 B4 B5 B6 B7 0C B2 0C E4 0A 5F 01 2C
				];
		};
	};
	mp2650-charger@5c {
		status = "okay";
		compatible = "oplus,mp2650-charger";
		reg = <0x5c 0>;

		qcom,mps_otg_en-gpio = <&pio 133 0x00>;		//check
		pinctrl-names = "mps_otg_en_active", "mps_otg_en_sleep", "mps_otg_en_default";
		pinctrl-0 = <&mps_otg_en_active>;
		pinctrl-1 = <&mps_otg_en_sleep>;
		pinctrl-2 = <&mps_otg_en_default>;
	};
	da9313-divider@68 {
		status = "okay";
		compatible = "oplus,da9313-divider";
		reg = <0x68 0>;
		qcom,ic_en_mode;
	};

	rk826_fastcg@0a{
		status = "okay";
		compatible = "oplus,rk826-fastcg";
		reg = <0x0a 0>;
		qcom,vooc-low-temp = <50>;
		qcom,oplus_batt_4400mv;
		qcom,support_vooc_by_normal_charger_path;
		//qcom,vooc_fw_update_newmethod;
		qcom,vooc-high-temp = <430>;
		qcom,vooc-low-soc = <1>;
		qcom,vooc-high-soc = <90>;
		qcom,vooc-fw-type = <6>;
		#include "mediatek/fastchg_fw/fw_svooc_10v6.3a_4.45v_fw_data_4400_oplus20601.dtsi"

		qcom,vooc_cool_bat_volt = <3450>;
		qcom,vooc_little_cool_bat_volt = <3400>;
		qcom,vooc_normal_bat_volt = <3350>;
		qcom,vooc_warm_bat_volt = <3300>;

		qcom,vooc_cool_bat_suspend_volt = <3450>;
		qcom,vooc_little_cool_bat_suspend_volt = <3400>;
		qcom,vooc_normal_bat_suspend_volt = <3350>;
		qcom,vooc_warm_bat_suspend_volt = <3300>;

		qcom,vooc_multistep_adjust_current_support;
		qcom,vooc_multistep_initial_batt_temp = <310>;
		qcom,vooc_strategy_normal_current = <0x06>;

		qcom,vooc-normal-to-little-cool-current = <0x05>;
		//qcom,vooc_batt_over_high_temp = <440>;//exit move to fastchg bin
		//qcom,vooc_batt_over_low_temp = <45>;//exit move to fastchg bin
		qcom,vooc_over_high_or_low_current = <0x02>;

		qcom,vooc_strategy1_batt_high_temp0 = <425>;
		qcom,vooc_strategy1_batt_high_temp1 = <430>;
		qcom,vooc_strategy1_batt_high_temp2 = <435>;
		qcom,vooc_strategy1_batt_low_temp2 = <420>;
		qcom,vooc_strategy1_batt_low_temp1 = <415>;
		qcom,vooc_strategy1_batt_low_temp0 = <400>;

		qcom,vooc_strategy1_high_current0 = <0x04>;//4A
		qcom,vooc_strategy1_high_current1 = <0x03>;//3A
		qcom,vooc_strategy1_high_current2 = <0x02>;//2A
		qcom,vooc_strategy1_low_current2 = <0x03>;//3A
		qcom,vooc_strategy1_low_current1 = <0x04>;//4A
		qcom,vooc_strategy1_low_current0 = <0x04>;//4A

		qcom,vooc_strategy2_batt_up_temp1 = <375>;
		qcom,vooc_strategy2_batt_up_down_temp2 = <380>;
		qcom,vooc_strategy2_batt_up_temp3 = <390>;
		qcom,vooc_strategy2_batt_up_down_temp4 = <400>;
		qcom,vooc_strategy2_batt_up_temp5 = <410>;
		qcom,vooc_strategy2_batt_up_temp6 = <415>;
		qcom,vooc_strategy2_high0_current = <0x05>;
		qcom,vooc_strategy2_high1_current = <0x04>;
		qcom,vooc_strategy2_high2_current = <0x03>;
		qcom,vooc_strategy2_high3_current = <0x02>;

		pinctrl-names = "switch1_act_switch2_act", "switch1_sleep_switch2_sleep",
						"switch1_act_switch3_act", "switch1_sleep_switch3_sleep",
						"switch1_act_switch2_sleep", "switch1_sleep_switch2_act",
						"clock_active","clock_sleep",
						"data_active","data_sleep",
						"reset_active","reset_sleep",
						"charging_switch1_ctr1_active","charging_switch1_ctr1_sleep",
						"vooc_asic_id_active","vooc_asic_id_sleep";
		pinctrl-0 = <&charging_switch1_active>;//USB_SW_CTRL1
		pinctrl-1 = <&charging_switch1_sleep>;//USB_SW_CTRL1
		pinctrl-2 = <&charging_switch1_active>;//USB_SW_CTRL1
		pinctrl-3 = <&charging_switch1_sleep>;//USB_SW_CTRL1
		pinctrl-4 = <&charging_switch1_active>;//USB_SW_CTRL1
		pinctrl-5 = <&charging_switch1_sleep>;//USB_SW_CTRL1
		pinctrl-6 = <&charging_clock_active>;//AP_CLK
		pinctrl-7 = <&charging_clock_sleep>;//AP_CLK
		pinctrl-8 = <&charging_data_active>;//AP_DATA
		pinctrl-9 = <&charging_data_sleep>;//AP_DATA
		pinctrl-10 = <&charging_reset_active>;//MCU_EN
		pinctrl-11 = <&charging_reset_sleep>;//MCU_EN
		pinctrl-12 = <&charging_switch1_ctr1_active>;//USB_SW_CTRL2
		pinctrl-13 = <&charging_switch1_ctr1_sleep>;//USB_SW_CTRL2
		pinctrl-14 = <&vooc_asic_id_active>;
		pinctrl-15 = <&vooc_asic_id_sleep>;
		qcom,charging_switch1-gpio 		= <&pio 191 0x00>;//USB_SW_CTRL1
		qcom,charging_switch1_ctr1-gpio 	= <&pio 186 0x00>;//USB_SW_CTRL2


		qcom,charging_reset-gpio 			= <&pio 189 0x00>;//MCU_EN
		qcom,charging_clock-gpio 			= <&pio 95 0x00>;//AP_CLK
		qcom,charging_data-gpio 			= <&pio 94 0x00>;//AP_DATA
		qcom,vooc_asic_id-gpio = <&pio 56 0x00>;
	};
};
//#endif OPLUS_FEATURE_CHG_BASIC

&apuart0 {
	pinctrl-names = "uart0_rx_gpio",
			"uart0_tx_gpio";
	pinctrl-0 = <&uart0_rx_gpio_input>;
	pinctrl-1 = <&uart0_tx_gpio_input>;
	status = "okay";
};

&pio {
	uart0_rx_gpio_input:uart0_rx_gpio@gpio92 {
		pins_cmd_dat {
			pinmux = <PINMUX_GPIO92__FUNC_GPIO92>;
			input-enable;
			slew-rate = <0>;
			bias-disable;
			//bias-pull-down = <00>;
		};
	};
	uart0_tx_gpio_input:uart0_tx_gpio@gpio93 {
		pins_cmd_dat {
			pinmux = <PINMUX_GPIO93__FUNC_GPIO93>;
			input-enable;
			slew-rate = <0>;
			bias-disable;
			//bias-pull-down = <00>;
		};
	};
};
//#ifdef OPLUS_FEATURE_CHG_BASIC
&pio {
	charger_pins_default: eint0default {
	};

	charger_pins_eint_output0: charger_gpio_as_output_low {		//check
		pins_cmd_dat {
			pinmux = <PINMUX_GPIO192__FUNC_GPIO192>;
			slew-rate = <1>;
			output-low;
		};
	};

	charger_pins_eint_output1: charger_gpio_as_output_high {	//check
		pins_cmd_dat {
			pinmux = <PINMUX_GPIO192__FUNC_GPIO192>;
			slew-rate = <1>;
			output-high;
		};
	};

	ship_sleep_gpio: ship_sleep {
		pins_cmd_dat {
			pinmux = <PINMUX_GPIO126__FUNC_GPIO126>;		//check
			slew-rate = <1>;
			output-low;
		};
	};

	ship_active_gpio: ship_active {
		pins_cmd_dat {
			pinmux = <PINMUX_GPIO126__FUNC_GPIO126>;		//check
			slew-rate = <1>;
			output-high;
		};
	};

	dischg_enable: dischg_enable {
		pins_cmd_dat {
			pinmux = <PINMUX_GPIO51__FUNC_GPIO51>;		//check
			slew-rate = <1>;							//0:input direction 1:output direction
			bias-pull-up = <00>;
			output-high;
		};
	};

	dischg_disable: dischg_disable {
		pins_cmd_dat {
			pinmux = <PINMUX_GPIO51__FUNC_GPIO51>;		//check
			slew-rate = <1>;
			bias-pull-down = <00>;
			output-low;
		};
	};

	
	ccdetect_active: ccdetect_active {
		pins_cmd_dat {
			pinmux = <PINMUX_GPIO5__FUNC_GPIO5>;
			input-enable;
			slew-rate = <0>;
			bias-disable;
		};
	};

	ccdetect_sleep: ccdetect_sleep {
		pins_cmd_dat {
			pinmux = <PINMUX_GPIO5__FUNC_GPIO5>;
			input-enable;
			slew-rate = <0>;
			bias-disable;
		};
	};
	
	/*shortc_active_gpio: shortc_active {
		pins_cmd_dat {
			pinmux = <PINMUX_GPIO121__FUNC_GPIO121>;
			input-enable;
			slew-rate = <0>;
			bias-pull-up;
		};
	};*/

	//Lukaili Add for camera flash led 
	chgvin_enable: chgvin_enable {
		pins_cmd_dat {
			pinmux = <PINMUX_GPIO9__FUNC_GPIO9>;				//check
			slew-rate = <1>;//0:input direction 1:output direction
			bias-pull-up = <00>;
			output-low;
		};
	};

	chgvin_disable: chgvin_disable {
		pins_cmd_dat {
			pinmux = <PINMUX_GPIO9__FUNC_GPIO9>;			//check
			slew-rate = <1>;
			bias-pull-down = <00>;
			output-high;
		};
	};

	pmic_chgfunc_enable: pmic_chgfunc_enable {
		pins_cmd_dat {
			pinmux = <PINMUX_GPIO26__FUNC_GPIO26>;			//check
			slew-rate = <1>;//0:input direction 1:output direction
			bias-pull-up = <00>;
			output-low;
		};
	};

	pmic_chgfunc_disable: pmic_chgfunc_disable {
		pins_cmd_dat {
			pinmux = <PINMUX_GPIO26__FUNC_GPIO26>;			//check
			slew-rate = <1>;
			bias-pull-down = <00>;
			output-high;
		};
	};

	//end Add for camera flash led 
};
//#endif OPLUS_FEATURE_CHG_BASIC
//#ifdef OPLUS_FEATURE_CHG_BASIC
&pio {
	charging_switch1_active: charging_switch1_active {
		pins_cmd_dat {
			pinmux = <PINMUX_GPIO191__FUNC_GPIO191>;		//check
			slew-rate = <1>;
			output-high;
		};
	};

	charging_switch1_sleep: charging_switch1_sleep {
		pins_cmd_dat {
			pinmux = <PINMUX_GPIO191__FUNC_GPIO191>;		//check
			slew-rate = <1>;
			output-low;
		};
	};

	charging_switch1_ctr1_active: charging_switch1_ctr1_active {
		pins_cmd_dat {
			pinmux = <PINMUX_GPIO186__FUNC_GPIO186>;		//empty
			slew-rate = <1>;
			bias-pull-up = <00>;
		};
	};
	charging_switch1_ctr1_sleep: charging_switch1_ctr1_sleep {
		pins_cmd_dat {
			pinmux = <PINMUX_GPIO186__FUNC_GPIO186>;		//empty
			slew-rate = <1>;
			output-low;
		};
	};
	
	charging_clock_active: charging_clock_active {
		pins_cmd_dat {
			pinmux = <PINMUX_GPIO95__FUNC_GPIO95>;		//check
			slew-rate = <0>;
			bias-pull-up = <00>;
		};
	};

	charging_clock_sleep: charging_clock_sleep {
		pins_cmd_dat {
			pinmux = <PINMUX_GPIO95__FUNC_GPIO95>;		//check
			slew-rate = <0>;
			bias-pull-down = <00>;
		};
	};

	charging_data_active: charging_data_active {
		pins_cmd_dat {
			pinmux = <PINMUX_GPIO94__FUNC_GPIO94>;		//check
			slew-rate = <0>;
			bias-pull-down = <00>;
		};
	};

	charging_data_sleep: charging_data_sleep {
		pins_cmd_dat {
			pinmux = <PINMUX_GPIO94__FUNC_GPIO94>;		//check
			slew-rate = <0>;
			bias-pull-down = <00>;
		};
	};

	charging_reset_active: charging_reset_active {
		pins_cmd_dat {
			pinmux = <PINMUX_GPIO189__FUNC_GPIO189>;	//check
			slew-rate = <1>;
			bias-pull-up = <00>;
		};
	};

	charging_reset_sleep: charging_reset_sleep {
		pins_cmd_dat {
			pinmux = <PINMUX_GPIO189__FUNC_GPIO189>;	//check
			slew-rate = <1>;
			bias-pull-down = <00>;
		};
	};
	vooc_asic_id_active: vooc_asic_id_active {
		pins_cmd_dat {
			pinmux = <PINMUX_GPIO56__FUNC_GPIO56>;
			input-enable;
			slew-rate = <0>;
			bias-pull-up;
		};
	};
	vooc_asic_id_sleep: vooc_asic_id_sleep {
		pins_cmd_dat {
			pinmux = <PINMUX_GPIO56__FUNC_GPIO56>;
			input-enable;
			slew-rate = <0>;
			bias-pull-down;
		};
	};
	mps_otg_en_active: mps_otg_en_active {
		pins_cmd_dat {
			pinmux = <PINMUX_GPIO133__FUNC_GPIO133>;		//check
			slew-rate = <1>;
			output-high;
		};
	};

	mps_otg_en_sleep: mps_otg_en_sleep {
		pins_cmd_dat {
			pinmux = <PINMUX_GPIO133__FUNC_GPIO133>;		//check
			slew-rate = <1>;
			output-low;
		};
	};

	mps_otg_en_default: mps_otg_en_default {
		pins_cmd_dat {
			pinmux = <PINMUX_GPIO133__FUNC_GPIO133>;		//check
			slew-rate = <1>;
			output-low;
		};
	};
};
//#endif  OPLUS_FEATURE_CHG_BASIC
//#ifdef OPLUS_FEATURE_CHG_BASIC
&mt6360_pmu {
	mt6360,intr_gpio_num = <24>; /* direct defined GPIO num */
	mt6360,intr_gpio = <&pio 24 0x0>;
};
//#endif  OPLUS_FEATURE_CHG_BASIC
&mt6360_pmic {
	pwr_off_seq = [04 00 02 02];
};
//#ifdef OPLUS_FEATURE_CHG_BASIC
&mt6360_typec {
	mt6360pd,intr_gpio_num = <25>; /* direct defined GPIO num */
	mt6360pd,intr_gpio = <&pio 25 0x0>;
//#ifdef OPLUS_FEATURE_FINGERPRINT
        mt6360pd,pcb_gpio = <&pio 55 0x0>;
        mt6360pd,pcb_gpio_num = <55>;
//#endif /* OPLUS_FEATURE_FINGERPRINT */
};
//#endif  OPLUS_FEATURE_CHG_BASIC
/* USB SWITCH GPIO start */
//#ifdef OPLUS_ARCH_EXTENDS
//#endif
/*
&pio {
	usb_default: usb_default {
	};

	gpio_redriver_c1_init: c1_init {
		pins_cmd_dat {
			pinmux = <PINMUX_GPIO113__FUNC_GPIO113>;
			slew-rate = <1>;
			output-low;
		};
	};

	gpio_redriver_c1_low: c1_low {
		pins_cmd_dat {
			pinmux = <PINMUX_GPIO113__FUNC_GPIO113>;
			slew-rate = <1>;
			output-low;
		};
	};

	gpio_redriver_c1_hiz: c1_highz {
		pins_cmd_dat {
			pinmux = <PINMUX_GPIO113__FUNC_GPIO113>;
			slew-rate= <0>;
			bias-disable;
		};
	};

	gpio_redriver_c1_high: c1_high {
		pins_cmd_dat {
			pinmux = <PINMUX_GPIO113__FUNC_GPIO113>;
			slew-rate = <1>;
			output-high;
		};
	};

	gpio_redriver_c2_init: c2_init {
		pins_cmd_dat {
			pinmux = <PINMUX_GPIO112__FUNC_GPIO112>;
			slew-rate = <1>;
			output-low;
		};
	};

	gpio_redriver_c2_low: c2_low {
		pins_cmd_dat {
			pinmux = <PINMUX_GPIO112__FUNC_GPIO112>;
			slew-rate = <1>;
			output-low;
		};
	};

	gpio_redriver_c2_hiz: c2_highz {
		pins_cmd_dat {
			pinmux = <PINMUX_GPIO112__FUNC_GPIO112>;
			slew-rate= <0>;
			bias-disable;
		};
	};

	gpio_redriver_c2_high: c2_high {
		pins_cmd_dat {
			pinmux = <PINMUX_GPIO112__FUNC_GPIO112>;
			slew-rate = <1>;
			output-high;
		};
	};

	gpio_u3_switch_sel1: u3_sw_sel1 {
		pins_cmd_dat {
			pinmux = <PINMUX_GPIO111__FUNC_GPIO111>;
			slew-rate = <1>;
			output-low;
		};
	};

	gpio_u3_switch_sel2: u3_sw_sel2 {
		pins_cmd_dat {
			pinmux = <PINMUX_GPIO111__FUNC_GPIO111>;
			slew-rate = <1>;
			output-high;
		};
	};

	gpio_u3_switch_enable: u3_sw_en {
	};

	gpio_u3_switch_disable: u3_sw_dis {
	};
};

&usb_c_pinctrl {
	pinctrl-names = "usb_default",
		"redrv_c1_init",
		"redrv_c1_low",
		"redrv_c1_hiz",
		"redrv_c1_high",
		"redrv_c2_init",
		"redrv_c2_low",
		"redrv_c2_hiz",
		"redrv_c2_high",
		"switch_sel1",
		"switch_sel2",
		"switch_enable",
		"switch_disable";

	pinctrl-0 = <&usb_default>;
	pinctrl-1 = <&gpio_redriver_c1_init>;
	pinctrl-2 = <&gpio_redriver_c1_low>;
	pinctrl-3 = <&gpio_redriver_c1_hiz>;
	pinctrl-4 = <&gpio_redriver_c1_high>;
	pinctrl-5 = <&gpio_redriver_c2_init>;
	pinctrl-6 = <&gpio_redriver_c2_low>;
	pinctrl-7 = <&gpio_redriver_c2_hiz>;
	pinctrl-8 = <&gpio_redriver_c2_high>;
	pinctrl-9 = <&gpio_u3_switch_sel1>;
	pinctrl-10 = <&gpio_u3_switch_sel2>;
	pinctrl-11 = <&gpio_u3_switch_enable>;
	pinctrl-12 = <&gpio_u3_switch_disable>;
	status = "okay";

	usb_switch-data {
		en_pin_num = <0>;
		en_pin_val = <0>;
		sel_pin_num = <111>;
		sel_pin_val = <1>;
		c1_pin_num = <113>;
		c1_pin_val = <2>;
		c2_pin_num = <112>;
		c2_pin_val = <1>;
	};
};
*/
/* USB SWITCH GPIO end */

//#ifdef OPLUS_FEATURE_NFC_BRINGUP
&i2c3 {
       status = "okay";
       nfc_nxp@28 {
               compatible = "nxp,pn544";
               reg = <0x28>;
               nxp,pn544-irq = <&pio 7 0x0>;
               nxp,pn544-ven = <&pio 16 0x0>;
               nxp,pn544-fw-dwnld = <&pio 6 0x0>;
               nxp,pn544-clkreq = <&pio 17 0x0>;
               interrupt-parent = <&pio>;
       };
       nfc_st21@8 {
           compatible = "st,st21nfc";
           reg = <0x8>;
           gpio-irq-std    = <&pio 7 0x0>;
           gpio-rst-std    = <&pio 16 0x0>;
           //gpio-pidle-std  = <&pio 16 0x0>;
           gpio-clkreq-std = <&pio 17 0x0>;
       };
};

&spi5 {
       status = "okay";
       st54spi@0 {
           compatible = "st,st54spi";
           reg = <0>;
           spi-max-frequency = <1000000> ;

           gpio-power_nreset = <6>;
           gpio-power_nreset-std = <&pio 6 0x0>;

           power_mode = "ST54H";

           pinctrl-names = "pinctrl_state_mode_idle", "pinctrl_state_mode_spi";
           pinctrl-0 = <&pinctrl_state_mode_idle>;
           pinctrl-1 = <&pinctrl_state_mode_spi>;
       };
};
//#endif /* OPLUS_FEATURE_NFC_BRINGUP */

//#ifdef OPLUS_FEATURE_NFC_BRINGUP
&pio {
    pinctrl_state_mode_idle: pinctrl_state_mode_idle {
        pins_cmd0_dat {
            pinmux = <PINMUX_GPIO37__FUNC_GPIO37>;
            input-enable;
            bias-pull-down;
        };
    };

    pinctrl_state_mode_spi: pinctrl_state_mode_spi {
        pins_cmd0_dat {
            pinmux = <PINMUX_GPIO37__FUNC_SPI5_A_CSB>;
            bias-disable;
        };
    };
};
//#endif /* OPLUS_FEATURE_NFC_BRINGUP */

/* GPS GPIO standardization start */
&pio {
	gps_pins_default: gps_default {
	};

	gps_l1_lna_pins_ol: gps_l1_lna@0 {
		pins_cmd_dat {
			pinmux = <PINMUX_GPIO162__FUNC_GPIO162>;
			output-low;
		};
	};
	gps_l1_lna_pins_dsp_ctrl: gps_l1_lna@1 {
		pins_cmd_dat {
			pinmux = <PINMUX_GPIO162__FUNC_GPS_L1_ELNA_EN>;
		};
	};
	gps_l1_lna_pins_oh: gps_l1_lna@2 {
		pins_cmd_dat {
			pinmux = <PINMUX_GPIO162__FUNC_GPIO162>;
			output-high;
		};
	};

	gps_l5_lna_pins_ol: gps_l5_lna@0 {
		pins_cmd_dat {
			pinmux = <PINMUX_GPIO163__FUNC_GPIO163>;
			output-low;
		};
	};
	gps_l5_lna_pins_dsp_ctrl: gps_l5_lna@1 {
		pins_cmd_dat {
			pinmux = <PINMUX_GPIO163__FUNC_GPS_L5_ELNA_EN>;
		};
	};
	gps_l5_lna_pins_oh: gps_l5_lna@2 {
		pins_cmd_dat {
			pinmux = <PINMUX_GPIO163__FUNC_GPIO163>;
			output-high;
		};
	};
};

&gps {
	pinctrl-names = "default",
		"gps_l1_lna_disable",
		"gps_l1_lna_dsp_ctrl",
		"gps_l1_lna_enable",
		"gps_l5_lna_disable",
		"gps_l5_lna_dsp_ctrl",
		"gps_l5_lna_enable";
	pinctrl-0 = <&gps_pins_default>;
	pinctrl-1 = <&gps_l1_lna_pins_ol>;
	pinctrl-2 = <&gps_l1_lna_pins_dsp_ctrl>;
	pinctrl-3 = <&gps_l1_lna_pins_oh>;
	pinctrl-4 = <&gps_l5_lna_pins_ol>;
	pinctrl-5 = <&gps_l5_lna_pins_dsp_ctrl>;
	pinctrl-6 = <&gps_l5_lna_pins_oh>;
	status = "okay";
};
/* GPS GPIO standardization end */

&dsi0 {
	status = "okay";
	#address-cells = <1>;
	#size-cells = <0>;
	/*#ifdef VENDOE_EDIT*/
	panel5@0 {
		compatible = "oplus20601_samsung_sofe03f_m_1080p_dsi_cmd";
		reg = <0>;
		pm-enable-gpios = <&pio 41 0>;
		reset-gpios = <&pio 42 0>;
		bias-gpios = <&pio 29 0>;
		ldo3-supply = <&mt_pmic_vmc_ldo_reg>;
		//pm8008ldo1-supply = <&L1P>;
		pinctrl-names = "default";
		port {
			panel_in5: endpoint {
				remote-endpoint = <&dsi_out>;
			};
		};
	};
	/*#endif*/
	ports {
		port {
			dsi_out: endpoint {
				remote-endpoint = <&panel_in5>;
			};
		};
	};
};
//#ifdef OPLUS_FEATURE_CHG_BASIC
&lk_charger{
	charger_by_buckboost;
	support_tuv_authentication;
};



&phy_tuning {
	compatible = "mediatek,phy_tuning";
	u2_vrt_ref = <7>;
	u2_term_ref = <7>;
	u2_enhance = <3>;

	host_u2_vrt_ref = <6>;
	host_u2_term_ref = <6>;
	host_u2_enhance = <2>;
};
&mt6360_typec{
	mt-tcpc,role_def = <4>;
};
//#endif OPLUS_FEATURE_CHG_BASIC
&swtp {
    compatible = "mediatek, swtp-eint";
    debounce = <512000>;
};
//#endif  /*VENDOR_EDIT*/
